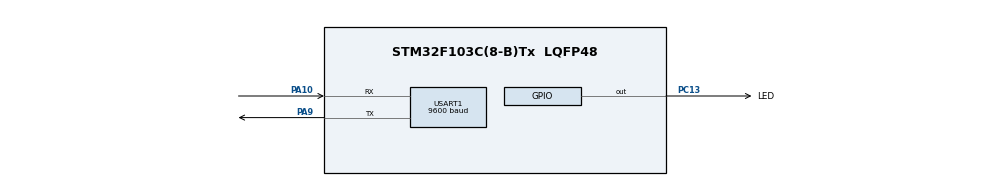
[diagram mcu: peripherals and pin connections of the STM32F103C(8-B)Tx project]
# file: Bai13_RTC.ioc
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Mcu.Family=STM32F1
PD1-OSC_OUT.Mode=HSE-External-Oscillator
PA10.Mode=Asynchronous
USART1.BaudRate=9600
PC13-TAMPER-RTC.Signal=GPIO_Output
VP_RTC_VS_RTC_Activate.Mode=RTC_Enabled
PD0-OSC_IN.Signal=RCC_OSC_IN
ProjectManager.StackSize=0x400
PD1-OSC_OUT.Signal=RCC_OSC_OUT
NVIC.RTC_IRQn=true\:0\:0\:false\:false\:true\:true\:true
PA13.Signal=SYS_JTMS-SWDIO
PA9.Mode=Asynchronous
ProjectManager.TargetToolchain=MDK-ARM V5
PA9.Signal=USART1_TX
RTC.Format=RTC_FORMAT_BIN
PD0-OSC_IN.Mode=HSE-External-Oscillator
RTC.Minutes=12
board=custom
RCC.RTCClockSelection=RCC_RTCCLKSOURCE_HSE_DIV128
PC13-TAMPER-RTC.GPIO_Label=LED
RCC.APB2Freq_Value=8000000
PA14.Mode=Serial_Wire
PA13.Mode=Serial_Wire
Mcu.Name=STM32F103C(8-B)Tx
RTC.Hours=12
Mcu.Package=LQFP48
USART1.VirtualMode=VM_ASYNC
PA10.Signal=USART1_RX
PA14.Signal=SYS_JTCK-SWCLK
VP_RTC_VS_RTC_Calendar.Mode=RTC_Calendar
ProjectManager.HeapSize=0x200
NVIC.PriorityGroup=NVIC_PRIORITYGROUP_4
RTC.Seconds=12
RCC.APB1Freq_Value=8000000
RTC.OutPut=RTC_OUTPUTSOURCE_SECOND

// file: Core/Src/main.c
/* USER CODE BEGIN Header */
/**
  ******************************************************************************
  * @file           : main.c
  * @brief          : Main program body
  ******************************************************************************
  * @attention
  *
  * <h2><center>&copy; Copyright (c) 2020 STMicroelectronics.
  * All rights reserved.</center></h2>
  *
  * This software component is licensed by ST under BSD 3-Clause license,
  * the "License"; You may not use this file except in compliance with the
  * License. You may obtain a copy of the License at:
  *                        opensource.org/licenses/BSD-3-Clause
  *
  ******************************************************************************
  */
/* USER CODE END Header */
#include "main.h"

/* USER CODE BEGIN Includes */
#include <stdio.h>
/* USER CODE END Includes */

RTC_HandleTypeDef hrtc;

UART_HandleTypeDef huart1;

/* USER CODE BEGIN PV */
RTC_TimeTypeDef sTime; // struct luu thoi gian
RTC_DateTypeDef sDate; // struct luu ngay thang nam
char buffer[10];
/* USER CODE END PV */

void SystemClock_Config(void);
static void MX_GPIO_Init(void);
static void MX_RTC_Init(void);
static void MX_USART1_UART_Init(void);

int main(void)
{

  /* MCU Configuration--------------------------------------------------------*/

  /* Reset of all peripherals, Initializes the Flash interface and the Systick. */
  HAL_Init();

  /* Configure the system clock */
  SystemClock_Config();

  /* Initialize all configured peripherals */
  MX_GPIO_Init();
  MX_RTC_Init();
  MX_USART1_UART_Init();

  /* Infinite loop */
  while (1)
  {

    /* USER CODE BEGIN 3 */
		HAL_RTC_GetTime(&hrtc, &sTime, RTC_FORMAT_BIN);
		HAL_RTC_GetDate(&hrtc, &sDate, RTC_FORMAT_BIN);
  }
  /* USER CODE END 3 */
}

void SystemClock_Config(void)
{
  RCC_OscInitTypeDef RCC_OscInitStruct = {0};
  RCC_ClkInitTypeDef RCC_ClkInitStruct = {0};
  RCC_PeriphCLKInitTypeDef PeriphClkInit = {0};

  /** Initializes the RCC Oscillators according to the specified parameters
  * in the RCC_OscInitTypeDef structure.
  */
  RCC_OscInitStruct.OscillatorType = RCC_OSCILLATORTYPE_HSI|RCC_OSCILLATORTYPE_HSE;
  RCC_OscInitStruct.HSEState = RCC_HSE_ON;
  RCC_OscInitStruct.HSIState = RCC_HSI_ON;
  RCC_OscInitStruct.HSICalibrationValue = RCC_HSICALIBRATION_DEFAULT;
  RCC_OscInitStruct.PLL.PLLState = RCC_PLL_NONE;
  if (HAL_RCC_OscConfig(&RCC_OscInitStruct) != HAL_OK)
  {
    Error_Handler();
  }
  /** Initializes the CPU, AHB and APB buses clocks
  */
  RCC_ClkInitStruct.ClockType = RCC_CLOCKTYPE_HCLK|RCC_CLOCKTYPE_SYSCLK
                              |RCC_CLOCKTYPE_PCLK1|RCC_CLOCKTYPE_PCLK2;
  RCC_ClkInitStruct.SYSCLKSource = RCC_SYSCLKSOURCE_HSI;
  RCC_ClkInitStruct.AHBCLKDivider = RCC_SYSCLK_DIV1;
  RCC_ClkInitStruct.APB1CLKDivider = RCC_HCLK_DIV1;
  RCC_ClkInitStruct.APB2CLKDivider = RCC_HCLK_DIV1;

  if (HAL_RCC_ClockConfig(&RCC_ClkInitStruct, FLASH_LATENCY_0) != HAL_OK)
  {
    Error_Handler();
  }
  PeriphClkInit.PeriphClockSelection = RCC_PERIPHCLK_RTC;
  PeriphClkInit.RTCClockSelection = RCC_RTCCLKSOURCE_HSE_DIV128;
  if (HAL_RCCEx_PeriphCLKConfig(&PeriphClkInit) != HAL_OK)
  {
    Error_Handler();
  }
}

static void MX_RTC_Init(void)
{

  RTC_TimeTypeDef sTime = {0};
  RTC_DateTypeDef DateToUpdate = {0};

  /** Initialize RTC Only
  */
  hrtc.Instance = RTC;
  hrtc.Init.AsynchPrediv = RTC_AUTO_1_SECOND;
  hrtc.Init.OutPut = RTC_OUTPUTSOURCE_SECOND;
  if (HAL_RTC_Init(&hrtc) != HAL_OK)
  {
    Error_Handler();
  }

  /* USER CODE BEGIN Check_RTC_BKUP */
	if(HAL_RTCEx_BKUPRead(&hrtc, RTC_BKP_DR1) != 0x2608) // kiem tra thanh ghi backup
	{
		/** Initialize RTC and set the Time and Date*/
		sTime.Hours = 12;
		sTime.Minutes = 12;
		sTime.Seconds = 12;

		if (HAL_RTC_SetTime(&hrtc, &sTime, RTC_FORMAT_BIN) != HAL_OK)
		{
			Error_Handler();
		}
		DateToUpdate.WeekDay = RTC_WEEKDAY_MONDAY;
		DateToUpdate.Month = RTC_MONTH_JANUARY;
		DateToUpdate.Date = 1;
		DateToUpdate.Year = 0;

		if (HAL_RTC_SetDate(&hrtc, &DateToUpdate, RTC_FORMAT_BIN) != HAL_OK)
		{
			Error_Handler();
		}
		HAL_RTCEx_BKUPWrite(&hrtc, RTC_BKP_DR1, 0x2608); // sau khi ghi time, date, ghi vao thanh ghi bkp
	}

  /* USER CODE END Check_RTC_BKUP */

  /** Initialize RTC and set the Time and Date
  */

}

static void MX_USART1_UART_Init(void)
{

  huart1.Instance = USART1;
  huart1.Init.BaudRate = 9600;
  huart1.Init.WordLength = UART_WORDLENGTH_8B;
  huart1.Init.StopBits = UART_STOPBITS_1;
  huart1.Init.Parity = UART_PARITY_NONE;
  huart1.Init.Mode = UART_MODE_TX_RX;
  huart1.Init.HwFlowCtl = UART_HWCONTROL_NONE;
  huart1.Init.OverSampling = UART_OVERSAMPLING_16;
  if (HAL_UART_Init(&huart1) != HAL_OK)
  {
    Error_Handler();
  }

}

static void MX_GPIO_Init(void)
{
  GPIO_InitTypeDef GPIO_InitStruct = {0};

  /* GPIO Ports Clock Enable */
  __HAL_RCC_GPIOC_CLK_ENABLE();
  __HAL_RCC_GPIOD_CLK_ENABLE();
  __HAL_RCC_GPIOA_CLK_ENABLE();

  /*Configure GPIO pin Output Level */
  HAL_GPIO_WritePin(LED_GPIO_Port, LED_Pin, GPIO_PIN_RESET);

  /*Configure GPIO pin : LED_Pin */
  GPIO_InitStruct.Pin = LED_Pin;
  GPIO_InitStruct.Mode = GPIO_MODE_OUTPUT_PP;
  GPIO_InitStruct.Pull = GPIO_NOPULL;
  GPIO_InitStruct.Speed = GPIO_SPEED_FREQ_LOW;
  HAL_GPIO_Init(LED_GPIO_Port, &GPIO_InitStruct);

}

void Error_Handler(void)
{
}

/************************ (C) COPYRIGHT STMicroelectronics *****END OF FILE****/
